# HDQ1W register map
Vendor: Texas Instruments
Peripheral module from a debugger description file (folder am437x).
Registers are 32-bit, read-only, no defined reset value unless marked. A register's access mark holds for its fields unless they carry their own. Offsets are as the file gives them; lines under a group give offsets from that group; [hi:lo] are bit positions; {n}, {i} and the like mark numbered series; 'fields as' and 'values as' point back to an identical list; <NAME> marks a mode.

## HDQ1W
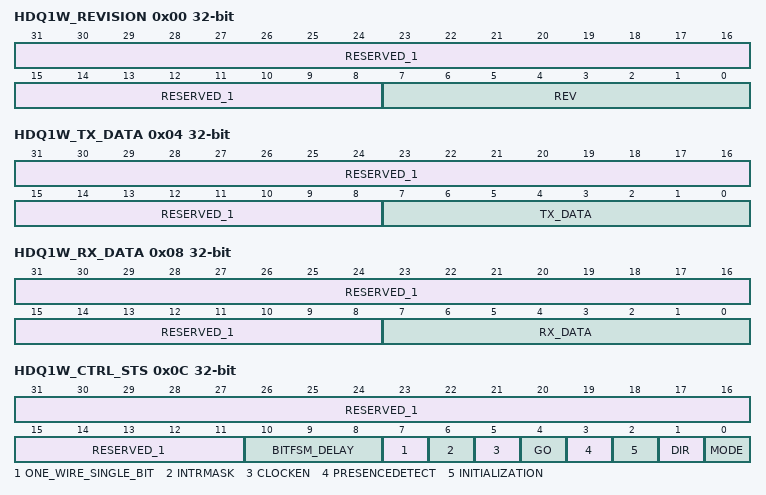
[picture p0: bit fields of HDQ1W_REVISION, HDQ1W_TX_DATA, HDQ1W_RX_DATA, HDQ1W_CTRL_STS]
0x00 HDQ1W_REVISION — This register contains the IP revision code
  [31:8] RESERVED_1 — Reads returns 0
  [7:0] REV — IP revision
0x04 HDQ1W_TX_DATA access per field — This register contains the data to be transmitted.
  [31:8] RESERVED_1 ro — Reads returns 0
  [7:0] TX_DATA rw — transmit data
0x08 HDQ1W_RX_DATA — This register contains the data to be received.
  [31:8] RESERVED_1 — Reads returns 0
  [7:0] RX_DATA — receive data
0x0C HDQ1W_CTRL_STS access per field — This register provides status information about the module.
  [31:11] RESERVED_1 rw — Reads returns 0
  [10:8] BITFSM_DELAY rw — BITFSM delay value
  [7] ONE_WIRE_SINGLE_BIT rw
  [6] INTRMASK rw
  [5] CLOCKEN rw
  [4] GO rw
  [3] PRESENCEDETECT ro
  [2] INITIALIZATION rw
  [1] DIR rw
  [0] MODE rw
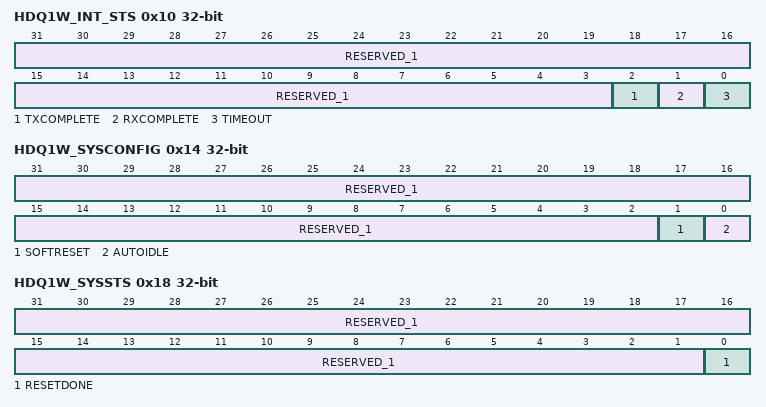
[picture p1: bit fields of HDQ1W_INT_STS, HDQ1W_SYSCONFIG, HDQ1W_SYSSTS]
0x10 HDQ1W_INT_STS — This register controls interrupts status
  [31:3] RESERVED_1 — Reads returns 0
  [2] TXCOMPLETE
  [1] RXCOMPLETE
  [0] TIMEOUT
0x14 HDQ1W_SYSCONFIG rw — This register controls various bits
  [31:2] RESERVED_1 — Reads returns 0
  [1] SOFTRESET — When '1', start softreset
  [0] AUTOIDLE — OCP idle
0x18 HDQ1W_SYSSTS — This register monitors the reset sequence.
  [31:1] RESERVED_1 — Reads returns 0
  [0] RESETDONE
